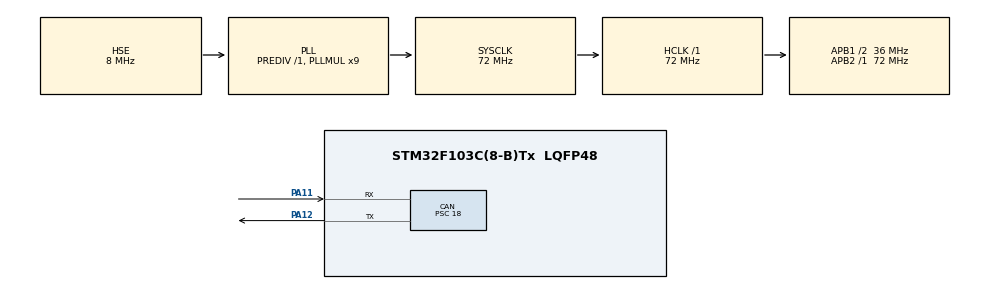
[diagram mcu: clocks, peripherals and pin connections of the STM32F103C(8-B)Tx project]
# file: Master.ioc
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CAN.BS1=CAN_BS1_13TQ
CAN.BS2=CAN_BS2_2TQ
CAN.CalculateBaudRate=125000
CAN.CalculateTimeBit=8000
CAN.CalculateTimeQuantum=500.0
CAN.Mode=CAN_MODE_NORMAL
CAN.NART=ENABLE
CAN.Prescaler=18
Mcu.Family=STM32F1
Mcu.Name=STM32F103C(8-B)Tx
Mcu.Package=LQFP48
NVIC.PriorityGroup=NVIC_PRIORITYGROUP_4
NVIC.USB_LP_CAN1_RX0_IRQn=true\:0\:0\:false\:false\:true\:true\:true\:true
PA11.Mode=CAN_Activate
PA11.Signal=CAN_RX
PA12.Mode=CAN_Activate
PA12.Signal=CAN_TX
PA13.Mode=Serial_Wire
PA13.Signal=SYS_JTMS-SWDIO
PA14.Mode=Serial_Wire
PA14.Signal=SYS_JTCK-SWCLK
PD0-OSC_IN.Mode=HSE-External-Oscillator
PD0-OSC_IN.Signal=RCC_OSC_IN
PD1-OSC_OUT.Mode=HSE-External-Oscillator
PD1-OSC_OUT.Signal=RCC_OSC_OUT
ProjectManager.HeapSize=0x200
ProjectManager.StackSize=0x400
ProjectManager.TargetToolchain=CMake
RCC.AHBFreq_Value=72000000
RCC.APB1CLKDivider=RCC_HCLK_DIV2
RCC.APB1Freq_Value=36000000
RCC.APB1TimFreq_Value=72000000
RCC.APB2Freq_Value=72000000
RCC.APB2TimFreq_Value=72000000
RCC.HCLKFreq_Value=72000000
RCC.PLLMUL=RCC_PLL_MUL9
RCC.PLLSourceVirtual=RCC_PLLSOURCE_HSE
RCC.SYSCLKFreq_VALUE=72000000
RCC.SYSCLKSource=RCC_SYSCLKSOURCE_PLLCLK
RCC.USBFreq_Value=72000000
board=custom

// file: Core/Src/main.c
/* USER CODE BEGIN Header */
/**
  ******************************************************************************
  * @file           : main.c
  * @brief          : Main program body
  ******************************************************************************
  * @attention
  *
  * Copyright (c) 2026 STMicroelectronics.
  * All rights reserved.
  *
  * This software is licensed under terms that can be found in the LICENSE file
  * in the root directory of this software component.
  * If no LICENSE file comes with this software, it is provided AS-IS.
  *
  ******************************************************************************
  */
/* USER CODE END Header */
#include "main.h"
#include "can.h"
#include "gpio.h"

/* USER CODE BEGIN PV */

CAN_TxHeaderTypeDef TxHeader;
CAN_RxHeaderTypeDef RxHeader;
CAN_FilterTypeDef  sFilterConfig;
uint8_t TxData[8] = {0x01, 0x02, 0x03, 0x04, 0x05, 0x06, 0x07, 0x08};
uint8_t RxData[8];
uint32_t TxMailbox;
volatile uint32_t can_rx_cnt = 0;

/* USER CODE END PV */

void SystemClock_Config(void);

int main(void)
{

  /* MCU Configuration--------------------------------------------------------*/

  /* Reset of all peripherals, Initializes the Flash interface and the Systick. */
  HAL_Init();

  /* Configure the system clock */
  SystemClock_Config();

  /* Initialize all configured peripherals */
  MX_GPIO_Init();
  MX_CAN_Init();
  /* USER CODE BEGIN 2 */

  //1.配置CAN过滤器

  //创建CAN过滤器配置的固定结构体的变量

  //对结构体中各成员赋值
  sFilterConfig.FilterActivation = ENABLE;
  sFilterConfig.FilterMode = CAN_FILTERMODE_IDMASK;
  sFilterConfig.FilterScale = CAN_FILTERSCALE_32BIT;
  sFilterConfig.FilterIdHigh = 0x0000;
  sFilterConfig.FilterIdLow = 0x0000;
  sFilterConfig.FilterMaskIdHigh = 0x0000;
  sFilterConfig.FilterMaskIdLow = 0x0000;
  sFilterConfig.FilterFIFOAssignment = CAN_RX_FIFO0;
  sFilterConfig.FilterBank = 0;
  sFilterConfig.SlaveStartFilterBank = 0;

  //使用设置过滤器函数将配置应用
  if(HAL_CAN_ConfigFilter(&hcan,&sFilterConfig)!=HAL_OK)
  {
    Error_Handler();
  }

  HAL_StatusTypeDef can_start_ret;

  can_start_ret = HAL_CAN_Start(&hcan);

  uint32_t can_err =HAL_CAN_GetError(&hcan);

  if(can_start_ret != HAL_OK)
  {
    while(1)
    {
    }
  }
  if(HAL_CAN_ActivateNotification(
          &hcan,
          CAN_IT_RX_FIFO0_MSG_PENDING)!=HAL_OK)
  {
    Error_Handler();
  }

  //3.开启接收中断通知_IT_RX_FIFO0_MSG_PENDING);

  /* USER CODE END 2 */

  /* Infinite loop */
  while (1)
  {

    /* USER CODE BEGIN 3 */

    //设置发送消息的结构体
    memset(&TxHeader, 0, sizeof(TxHeader));

    TxHeader.StdId = 0x123;
    TxHeader.IDE   = CAN_ID_STD;
    TxHeader.RTR   = CAN_RTR_DATA;
    TxHeader.DLC   = 8;

    if (HAL_CAN_AddTxMessage(&hcan, &TxHeader, TxData, &TxMailbox) != HAL_OK)
    {
      // 发送失败处理（可在这里打断点查看错误）
    }
    uint32_t mailPending =
        HAL_CAN_IsTxMessagePending(
            &hcan,
            CAN_TX_MAILBOX0 |
            CAN_TX_MAILBOX1 |
            CAN_TX_MAILBOX2);

    HAL_StatusTypeDef tx_ret;

    tx_ret = HAL_CAN_AddTxMessage(
                &hcan,
                &TxHeader,
                TxData,
                &TxMailbox);

    uint32_t txFree =
            HAL_CAN_GetTxMailboxesFreeLevel(&hcan);

    uint32_t fill =
            HAL_CAN_GetRxFifoFillLevel(
                &hcan,
                CAN_RX_FIFO0);
    /* 发送数据 */
    if (HAL_CAN_AddTxMessage(&hcan,
                         &TxHeader,
                         TxData,
                         &TxMailbox) != HAL_OK)
    {
      uint32_t err = HAL_CAN_GetError(&hcan);

      Error_Handler();
    }

    HAL_Delay(1000); // 延时1秒，避免疯狂发送导致刷屏

  }

  /* USER CODE END 3 */
}

void SystemClock_Config(void)
{
  RCC_OscInitTypeDef RCC_OscInitStruct = {0};
  RCC_ClkInitTypeDef RCC_ClkInitStruct = {0};

  /** Initializes the RCC Oscillators according to the specified parameters
  * in the RCC_OscInitTypeDef structure.
  */
  RCC_OscInitStruct.OscillatorType = RCC_OSCILLATORTYPE_HSE;
  RCC_OscInitStruct.HSEState = RCC_HSE_ON;
  RCC_OscInitStruct.HSEPredivValue = RCC_HSE_PREDIV_DIV1;
  RCC_OscInitStruct.HSIState = RCC_HSI_ON;
  RCC_OscInitStruct.PLL.PLLState = RCC_PLL_ON;
  RCC_OscInitStruct.PLL.PLLSource = RCC_PLLSOURCE_HSE;
  RCC_OscInitStruct.PLL.PLLMUL = RCC_PLL_MUL9;
  if (HAL_RCC_OscConfig(&RCC_OscInitStruct) != HAL_OK)
  {
    Error_Handler();
  }

  /** Initializes the CPU, AHB and APB buses clocks
  */
  RCC_ClkInitStruct.ClockType = RCC_CLOCKTYPE_HCLK|RCC_CLOCKTYPE_SYSCLK
                              |RCC_CLOCKTYPE_PCLK1|RCC_CLOCKTYPE_PCLK2;
  RCC_ClkInitStruct.SYSCLKSource = RCC_SYSCLKSOURCE_PLLCLK;
  RCC_ClkInitStruct.AHBCLKDivider = RCC_SYSCLK_DIV1;
  RCC_ClkInitStruct.APB1CLKDivider = RCC_HCLK_DIV2;
  RCC_ClkInitStruct.APB2CLKDivider = RCC_HCLK_DIV1;

  if (HAL_RCC_ClockConfig(&RCC_ClkInitStruct, FLASH_LATENCY_2) != HAL_OK)
  {
    Error_Handler();
  }
}

/* USER CODE BEGIN 4 */

  /* 从FIFO0取出数据 */
  void HAL_CAN_RxFifo0MsgPendingCallback(CAN_HandleTypeDef *hcan)
  {
  // ← 这里打断点

  if(HAL_CAN_GetRxMessage(
          hcan,
          CAN_RX_FIFO0,
          &RxHeader,
          RxData) == HAL_OK)
  {
    //。。。
}
  }
/* USER CODE END 4 */

void Error_Handler(void)
{
    __disable_irq();
    while (1)
    {
    }
}
